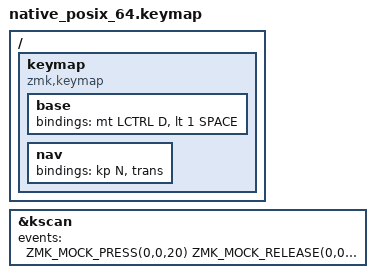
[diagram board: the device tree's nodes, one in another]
#include <dt-bindings/zmk/keys.h>
#include <behaviors.dtsi>
#include <dt-bindings/zmk/kscan_mock.h>
#include "../../../config/hold_tap.dtsi"

/ {
    keymap {
        compatible = "zmk,keymap";
        base { bindings = <&mt LCTRL D &lt 1 SPACE>; };
        nav { bindings = <&kp N &trans>; };
    };
};
&kscan {
    events = <
        ZMK_MOCK_PRESS(0,0,20)
        ZMK_MOCK_RELEASE(0,0,20)
        ZMK_MOCK_PRESS(0,0,200)
        ZMK_MOCK_RELEASE(0,0,300)
        ZMK_MOCK_PRESS(0,1,20)
        ZMK_MOCK_RELEASE(0,1,20)
        ZMK_MOCK_PRESS(0,1,200)
        ZMK_MOCK_PRESS(0,0,20)
        ZMK_MOCK_RELEASE(0,0,20)
        ZMK_MOCK_RELEASE(0,1,10)
    >;
};
